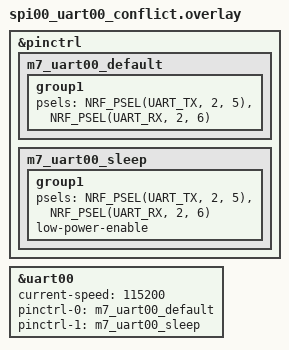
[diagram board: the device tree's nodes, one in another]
/**
 * @file spi00_uart00_conflict.overlay
 * @brief 공유 hardware instance인 SPI00과 uart00을 동시 활성화합니다.
 *
 * SPDX-License-Identifier: MIT
 */

#include <zephyr/dt-bindings/pinctrl/nrf-pinctrl.h>

&pinctrl {
	m7_uart00_default: m7_uart00_default {
		group1 {
			psels = <NRF_PSEL(UART_TX, 2, 5)>,
				<NRF_PSEL(UART_RX, 2, 6)>;
		};
	};

	m7_uart00_sleep: m7_uart00_sleep {
		group1 {
			psels = <NRF_PSEL(UART_TX, 2, 5)>,
				<NRF_PSEL(UART_RX, 2, 6)>;
			low-power-enable;
		};
	};
};

&uart00 {
	current-speed = <115200>;
	pinctrl-0 = <&m7_uart00_default>;
	pinctrl-1 = <&m7_uart00_sleep>;
	pinctrl-names = "default", "sleep";
	status = "okay";
};
